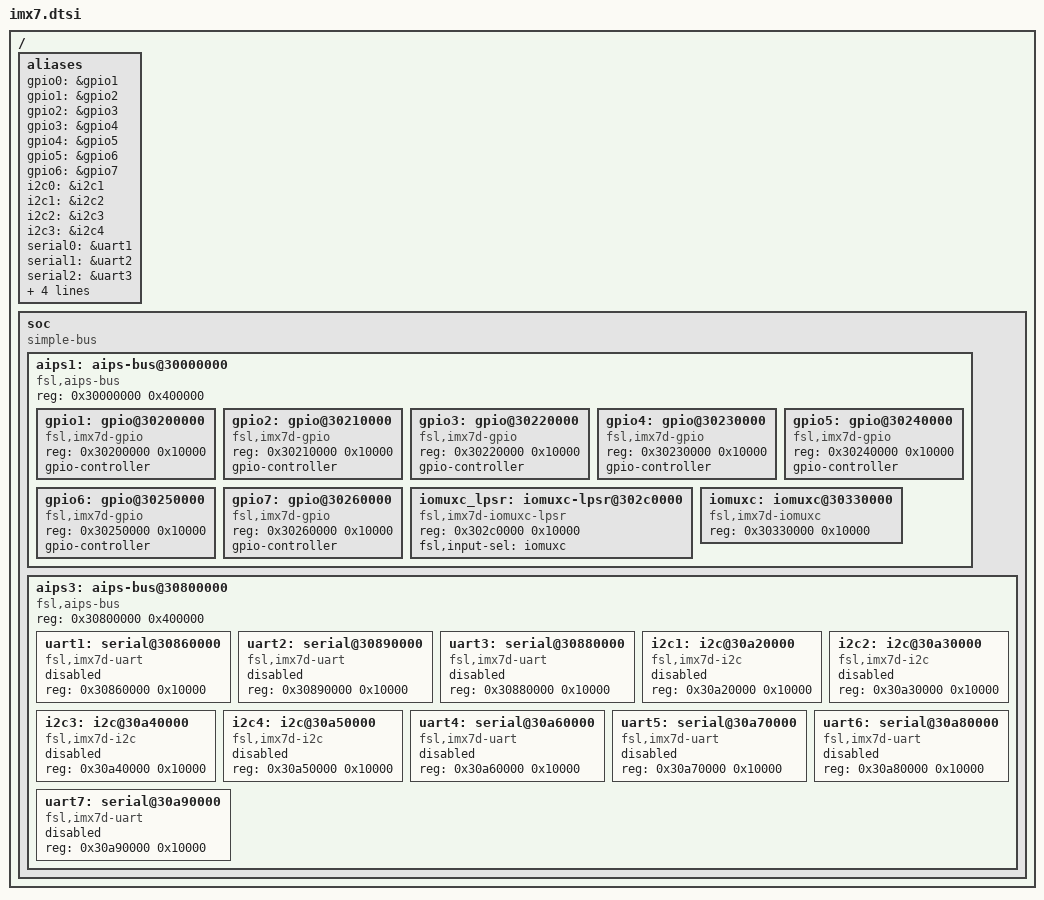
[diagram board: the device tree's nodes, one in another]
/*
 * Copyright 2016 Toradex AG
 *
 * SPDX-License-Identifier:     GPL-2.0+ or X11
 */
#include "imx7d-pinfunc.h"
#include "skeleton.dtsi"

/ {
	aliases {
		gpio0 = &gpio1;
		gpio1 = &gpio2;
		gpio2 = &gpio3;
		gpio3 = &gpio4;
		gpio4 = &gpio5;
		gpio5 = &gpio6;
		gpio6 = &gpio7;
		i2c0 = &i2c1;
		i2c1 = &i2c2;
		i2c2 = &i2c3;
		i2c3 = &i2c4;
		serial0 = &uart1;
		serial1 = &uart2;
		serial2 = &uart3;
		serial3 = &uart4;
		serial4 = &uart5;
		serial5 = &uart6;
		serial6 = &uart7;
	};

	soc {
		#address-cells = <1>;
		#size-cells = <1>;
		compatible = "simple-bus";
		ranges;

		aips1: aips-bus@30000000 {
			compatible = "fsl,aips-bus", "simple-bus";
			#address-cells = <1>;
			#size-cells = <1>;
			reg = <0x30000000 0x400000>;
			ranges;

			gpio1: gpio@30200000 {
				compatible = "fsl,imx7d-gpio", "fsl,imx35-gpio";
				reg = <0x30200000 0x10000>;
				gpio-controller;
				#gpio-cells = <2>;
			};

			gpio2: gpio@30210000 {
				compatible = "fsl,imx7d-gpio", "fsl,imx35-gpio";
				reg = <0x30210000 0x10000>;
				gpio-controller;
				#gpio-cells = <2>;
			};

			gpio3: gpio@30220000 {
				compatible = "fsl,imx7d-gpio", "fsl,imx35-gpio";
				reg = <0x30220000 0x10000>;
				gpio-controller;
				#gpio-cells = <2>;
			};

			gpio4: gpio@30230000 {
				compatible = "fsl,imx7d-gpio", "fsl,imx35-gpio";
				reg = <0x30230000 0x10000>;
				gpio-controller;
				#gpio-cells = <2>;
			};

			gpio5: gpio@30240000 {
				compatible = "fsl,imx7d-gpio", "fsl,imx35-gpio";
				reg = <0x30240000 0x10000>;
				gpio-controller;
				#gpio-cells = <2>;
			};

			gpio6: gpio@30250000 {
				compatible = "fsl,imx7d-gpio", "fsl,imx35-gpio";
				reg = <0x30250000 0x10000>;
				gpio-controller;
				#gpio-cells = <2>;
			};

			gpio7: gpio@30260000 {
				compatible = "fsl,imx7d-gpio", "fsl,imx35-gpio";
				reg = <0x30260000 0x10000>;
				gpio-controller;
				#gpio-cells = <2>;
			};

			iomuxc_lpsr: iomuxc-lpsr@302c0000 {
				compatible = "fsl,imx7d-iomuxc-lpsr";
				reg = <0x302c0000 0x10000>;
				fsl,input-sel = <&iomuxc>;
			};

			iomuxc: iomuxc@30330000 {
				compatible = "fsl,imx7d-iomuxc";
				reg = <0x30330000 0x10000>;
			};
		};

		aips3: aips-bus@30800000 {
			compatible = "fsl,aips-bus", "simple-bus";
			#address-cells = <1>;
			#size-cells = <1>;
			reg = <0x30800000 0x400000>;
			ranges;

			uart1: serial@30860000 {
				compatible = "fsl,imx7d-uart",
					     "fsl,imx6q-uart";
				reg = <0x30860000 0x10000>;
				status = "disabled";
			};

			uart2: serial@30890000 {
				compatible = "fsl,imx7d-uart",
					     "fsl,imx6q-uart";
				reg = <0x30890000 0x10000>;
				status = "disabled";
			};

			uart3: serial@30880000 {
				compatible = "fsl,imx7d-uart",
					     "fsl,imx6q-uart";
				reg = <0x30880000 0x10000>;
				status = "disabled";
			};

			i2c1: i2c@30a20000 {
				#address-cells = <1>;
				#size-cells = <0>;
				compatible = "fsl,imx7d-i2c", "fsl,imx21-i2c";
				reg = <0x30a20000 0x10000>;
				status = "disabled";
			};

			i2c2: i2c@30a30000 {
				#address-cells = <1>;
				#size-cells = <0>;
				compatible = "fsl,imx7d-i2c", "fsl,imx21-i2c";
				reg = <0x30a30000 0x10000>;
				status = "disabled";
			};

			i2c3: i2c@30a40000 {
				#address-cells = <1>;
				#size-cells = <0>;
				compatible = "fsl,imx7d-i2c", "fsl,imx21-i2c";
				reg = <0x30a40000 0x10000>;
				status = "disabled";
			};

			i2c4: i2c@30a50000 {
				#address-cells = <1>;
				#size-cells = <0>;
				compatible = "fsl,imx7d-i2c", "fsl,imx21-i2c";
				reg = <0x30a50000 0x10000>;
				status = "disabled";
			};

			uart4: serial@30a60000 {
				compatible = "fsl,imx7d-uart",
					     "fsl,imx6q-uart";
				reg = <0x30a60000 0x10000>;
				status = "disabled";
			};

			uart5: serial@30a70000 {
				compatible = "fsl,imx7d-uart",
					     "fsl,imx6q-uart";
				reg = <0x30a70000 0x10000>;
				status = "disabled";
			};

			uart6: serial@30a80000 {
				compatible = "fsl,imx7d-uart",
					     "fsl,imx6q-uart";
				reg = <0x30a80000 0x10000>;
				status = "disabled";
			};

			uart7: serial@30a90000 {
				compatible = "fsl,imx7d-uart",
					     "fsl,imx6q-uart";
				reg = <0x30a90000 0x10000>;
				status = "disabled";
			};
		};
	};
};
